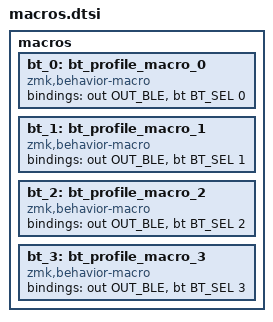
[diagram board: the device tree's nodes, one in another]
#include <dts/bindings/macros/zmk,macro-control-mode-press.yaml>
#include <dts/bindings/macros/zmk,macro-control-mode-release.yaml>
#include <dts/bindings/macros/zmk,macro-control-mode-tap.yaml>
#include <dts/bindings/macros/zmk,macro-control-tap-time.yaml>
#include <dts/bindings/macros/zmk,macro-control-wait-time.yaml>
#include <dts/bindings/macros/zmk,macro-param-1to1.yaml>
#include <dts/bindings/macros/zmk,macro-param-1to2.yaml>
#include <dts/bindings/macros/zmk,macro-param-2to1.yaml>
#include <dts/bindings/macros/zmk,macro-pause-for-release.yaml>


macros {
    bt_0: bt_profile_macro_0 {
        compatible = "zmk,behavior-macro";
        #binding-cells = <0>;
        bindings
            = <&out OUT_BLE>,
              <&bt BT_SEL 0>;
    };

    bt_1: bt_profile_macro_1 {
        compatible = "zmk,behavior-macro";
        #binding-cells = <0>;
        bindings
            = <&out OUT_BLE>,
              <&bt BT_SEL 1>;
    };

    bt_2: bt_profile_macro_2 {
        compatible = "zmk,behavior-macro";
        #binding-cells = <0>;
        bindings
            = <&out OUT_BLE>,
              <&bt BT_SEL 2>;
    };

    bt_3: bt_profile_macro_3 {
        compatible = "zmk,behavior-macro";
        #binding-cells = <0>;
        bindings
            = <&out OUT_BLE>,
              <&bt BT_SEL 3>;
    };
};
